AUTOSAR XML (schema 4-1-3)
standard types defined: boolean, uint16, uint32, uint8
package /UAES/ASW/CompuMethods
  compu method CM_boolean: 0=FALSE, 1=TRUE
package /UAES/ASW/DataConstrs
  range DC_boolean: raw 0..1
  range DC_uint16: raw 0..65535
  range DC_uint32: raw 0..4294967295
  range DC_uint8: raw 0..255
package /UAES/ASW/DataTypeMappingSets
  data type mapping set DTMS_ElecDoorHndl_Ctrl
package /UAES/ASW/PortInterfaces
  49 x sender receiver interface:
    gASI_bPowerOnReset: invalidation-policy{data-element=gASI_bPowerOnReset/Val, handle-invalid=DONT-INVALIDATE}
      data Val: sw-calibration-access=READ-ONLY, type=boolean
    gCAN_bLCK_RearLeftDoorHandle: invalidation-policy{data-element=gCAN_bLCK_RearLeftDoorHandle/Val, handle-invalid=DONT-INVALIDATE}
      data Val: sw-calibration-access=READ-ONLY, type=boolean
    gCAN_bLCK_RearRightDoorHandle: invalidation-policy{data-element=gCAN_bLCK_RearRightDoorHandle/Val, handle-invalid=DONT-INVALIDATE}
      data Val: sw-calibration-access=READ-ONLY, type=boolean
    gCAN_u8LCK_DoorHandleCommandActionType: invalidation-policy{data-element=gCAN_u8LCK_DoorHandleCommandActionType/Val, handle-invalid=DONT-INVALIDATE}
      data Val: sw-calibration-access=READ-ONLY, type=uint8
    gEDH_bRLDoorHndlMotorTrigUds: invalidation-policy{data-element=gEDH_bRLDoorHndlMotorTrigUds/Val, handle-invalid=DONT-INVALIDATE}
      data Val: sw-calibration-access=READ-ONLY, type=boolean
    gEDH_bRLHallSupplyOutput: invalidation-policy{data-element=gEDH_bRLHallSupplyOutput/Val, handle-invalid=DONT-INVALIDATE}
      data Val: sw-calibration-access=READ-ONLY, type=boolean
    gEDH_bRRDoorHndlMotorTrigUds: invalidation-policy{data-element=gEDH_bRRDoorHndlMotorTrigUds/Val, handle-invalid=DONT-INVALIDATE}
      data Val: sw-calibration-access=READ-ONLY, type=boolean
    gEDH_bRRHallSupplyOutput: invalidation-policy{data-element=gEDH_bRRHallSupplyOutput/Val, handle-invalid=DONT-INVALIDATE}
      data Val: sw-calibration-access=READ-ONLY, type=boolean
    gEDH_u16RLDoorHandleBigPosition: invalidation-policy{data-element=gEDH_u16RLDoorHandleBigPosition/Val, handle-invalid=DONT-INVALIDATE}
      data Val: sw-calibration-access=READ-ONLY, type=uint16
    gEDH_u16RLDoorHandlePosition: invalidation-policy{data-element=gEDH_u16RLDoorHandlePosition/Val, handle-invalid=DONT-INVALIDATE}
      data Val: sw-calibration-access=READ-ONLY, type=uint16
    gEDH_u16RLDoorHandleSmallPosition: invalidation-policy{data-element=gEDH_u16RLDoorHandleSmallPosition/Val, handle-invalid=DONT-INVALIDATE}
      data Val: sw-calibration-access=READ-ONLY, type=uint16
    gEDH_u16RLHallCnt: invalidation-policy{data-element=gEDH_u16RLHallCnt/Val, handle-invalid=DONT-INVALIDATE}
      data Val: sw-calibration-access=READ-ONLY, type=uint16
    gEDH_u16RLHallWidth: invalidation-policy{data-element=gEDH_u16RLHallWidth/Val, handle-invalid=DONT-INVALIDATE}
      data Val: sw-calibration-access=READ-ONLY, type=uint16
    gEDH_u16RRDoorHandleBigPosition: invalidation-policy{data-element=gEDH_u16RRDoorHandleBigPosition/Val, handle-invalid=DONT-INVALIDATE}
      data Val: sw-calibration-access=READ-ONLY, type=uint16
    gEDH_u16RRDoorHandlePosition: invalidation-policy{data-element=gEDH_u16RRDoorHandlePosition/Val, handle-invalid=DONT-INVALIDATE}
      data Val: sw-calibration-access=READ-ONLY, type=uint16
    gEDH_u16RRDoorHandleSmallPosition: invalidation-policy{data-element=gEDH_u16RRDoorHandleSmallPosition/Val, handle-invalid=DONT-INVALIDATE}
      data Val: sw-calibration-access=READ-ONLY, type=uint16
    gEDH_u16RRHallCnt: invalidation-policy{data-element=gEDH_u16RRHallCnt/Val, handle-invalid=DONT-INVALIDATE}
      data Val: sw-calibration-access=READ-ONLY, type=uint16
    gEDH_u16RRHallWidth: invalidation-policy{data-element=gEDH_u16RRHallWidth/Val, handle-invalid=DONT-INVALIDATE}
      data Val: sw-calibration-access=READ-ONLY, type=uint16
    gEDH_u32AllowSleep_Local: invalidation-policy{data-element=gEDH_u32AllowSleep_Local/Val, handle-invalid=DONT-INVALIDATE}
      data Val: sw-calibration-access=READ-ONLY, type=uint32
    gEDH_u32AllowSleep_NW: invalidation-policy{data-element=gEDH_u32AllowSleep_NW/Val, handle-invalid=DONT-INVALIDATE}
      data Val: sw-calibration-access=READ-ONLY, type=uint32
    gEDH_u8LCK_RearLeftDoorHandleAction: invalidation-policy{data-element=gEDH_u8LCK_RearLeftDoorHandleAction/Val, handle-invalid=DONT-INVALIDATE}
      data Val: sw-calibration-access=READ-ONLY, type=uint8
    gEDH_u8LCK_RearLeftDoorHandlePosition: invalidation-policy{data-element=gEDH_u8LCK_RearLeftDoorHandlePosition/Val, handle-invalid=DONT-INVALIDATE}
      data Val: sw-calibration-access=READ-ONLY, type=uint8
    gEDH_u8LCK_RearRightDoorHandleAction: invalidation-policy{data-element=gEDH_u8LCK_RearRightDoorHandleAction/Val, handle-invalid=DONT-INVALIDATE}
      data Val: sw-calibration-access=READ-ONLY, type=uint8
    gEDH_u8LCK_RearRightDoorHandlePosition: invalidation-policy{data-element=gEDH_u8LCK_RearRightDoorHandlePosition/Val, handle-invalid=DONT-INVALIDATE}
      data Val: sw-calibration-access=READ-ONLY, type=uint8
    gEDH_u8RLDoorHandleBigPositionWrtCnt: invalidation-policy{data-element=gEDH_u8RLDoorHandleBigPositionWrtCnt/Val, handle-invalid=DONT-INVALIDATE}
      data Val: sw-calibration-access=READ-ONLY, type=uint8
    gEDH_u8RLDoorHandleMotorOutput: invalidation-policy{data-element=gEDH_u8RLDoorHandleMotorOutput/Val, handle-invalid=DONT-INVALIDATE}
      data Val: sw-calibration-access=READ-ONLY, type=uint8
    gEDH_u8RLDoorHandlePositionWrtCnt: invalidation-policy{data-element=gEDH_u8RLDoorHandlePositionWrtCnt/Val, handle-invalid=DONT-INVALIDATE}
      data Val: sw-calibration-access=READ-ONLY, type=uint8
    gEDH_u8RLDoorHandlePWMOutput: invalidation-policy{data-element=gEDH_u8RLDoorHandlePWMOutput/Val, handle-invalid=DONT-INVALIDATE}
      data Val: sw-calibration-access=READ-ONLY, type=uint8
    gEDH_u8RLDoorHandleSmallPositionWrtCnt: invalidation-policy{data-element=gEDH_u8RLDoorHandleSmallPositionWrtCnt/Val, handle-invalid=DONT-INVALIDATE}
      data Val: sw-calibration-access=READ-ONLY, type=uint8
    gEDH_u8RLDoorHndlMotorUds: invalidation-policy{data-element=gEDH_u8RLDoorHndlMotorUds/Val, handle-invalid=DONT-INVALIDATE}
      data Val: sw-calibration-access=READ-ONLY, type=uint8
    gEDH_u8RRDoorHandleBigPositionWrtCnt: invalidation-policy{data-element=gEDH_u8RRDoorHandleBigPositionWrtCnt/Val, handle-invalid=DONT-INVALIDATE}
      data Val: sw-calibration-access=READ-ONLY, type=uint8
    gEDH_u8RRDoorHandleMotorOutput: invalidation-policy{data-element=gEDH_u8RRDoorHandleMotorOutput/Val, handle-invalid=DONT-INVALIDATE}
      data Val: sw-calibration-access=READ-ONLY, type=uint8
    gEDH_u8RRDoorHandlePositionWrtCnt: invalidation-policy{data-element=gEDH_u8RRDoorHandlePositionWrtCnt/Val, handle-invalid=DONT-INVALIDATE}
      data Val: sw-calibration-access=READ-ONLY, type=uint8
    gEDH_u8RRDoorHandlePWMOutput: invalidation-policy{data-element=gEDH_u8RRDoorHandlePWMOutput/Val, handle-invalid=DONT-INVALIDATE}
      data Val: sw-calibration-access=READ-ONLY, type=uint8
    gEDH_u8RRDoorHandleSmallPositionWrtCnt: invalidation-policy{data-element=gEDH_u8RRDoorHandleSmallPositionWrtCnt/Val, handle-invalid=DONT-INVALIDATE}
      data Val: sw-calibration-access=READ-ONLY, type=uint8
    gEDH_u8RRDoorHndlMotorUds: invalidation-policy{data-element=gEDH_u8RRDoorHndlMotorUds/Val, handle-invalid=DONT-INVALIDATE}
      data Val: sw-calibration-access=READ-ONLY, type=uint8
    gElecDoorHndl_u8RLDoorHndlMotorPs: invalidation-policy{data-element=gElecDoorHndl_u8RLDoorHndlMotorPs/Val, handle-invalid=DONT-INVALIDATE}
      data Val: sw-calibration-access=READ-ONLY, type=uint8
    gElecDoorHndl_u8RRDoorHndlMotorPs: invalidation-policy{data-element=gElecDoorHndl_u8RRDoorHndlMotorPs/Val, handle-invalid=DONT-INVALIDATE}
      data Val: sw-calibration-access=READ-ONLY, type=uint8
    gNVM_u16RLDoorHandleBigPosition: invalidation-policy{data-element=gNVM_u16RLDoorHandleBigPosition/Val, handle-invalid=DONT-INVALIDATE}
      data Val: sw-calibration-access=READ-ONLY, type=uint16
    gNVM_u16RLDoorHandlePosition: invalidation-policy{data-element=gNVM_u16RLDoorHandlePosition/Val, handle-invalid=DONT-INVALIDATE}
      data Val: sw-calibration-access=READ-ONLY, type=uint16
    gNVM_u16RLDoorHandleSmallPosition: invalidation-policy{data-element=gNVM_u16RLDoorHandleSmallPosition/Val, handle-invalid=DONT-INVALIDATE}
      data Val: sw-calibration-access=READ-ONLY, type=uint16
    gNVM_u16RRDoorHandleBigPosition: invalidation-policy{data-element=gNVM_u16RRDoorHandleBigPosition/Val, handle-invalid=DONT-INVALIDATE}
      data Val: sw-calibration-access=READ-ONLY, type=uint16
    gNVM_u16RRDoorHandlePosition: invalidation-policy{data-element=gNVM_u16RRDoorHandlePosition/Val, handle-invalid=DONT-INVALIDATE}
      data Val: sw-calibration-access=READ-ONLY, type=uint16
    gNVM_u16RRDoorHandleSmallPosition: invalidation-policy{data-element=gNVM_u16RRDoorHandleSmallPosition/Val, handle-invalid=DONT-INVALIDATE}
      data Val: sw-calibration-access=READ-ONLY, type=uint16
    gPRM_u8tDoorHandleEmergencyCfg: invalidation-policy{data-element=gPRM_u8tDoorHandleEmergencyCfg/Val, handle-invalid=DONT-INVALIDATE}
      data Val: sw-calibration-access=READ-ONLY, type=uint8
    gPRM_u8tDoorHandleForceCfg: invalidation-policy{data-element=gPRM_u8tDoorHandleForceCfg/Val, handle-invalid=DONT-INVALIDATE}
      data Val: sw-calibration-access=READ-ONLY, type=uint8
    gPRM_u8tDoorHandleSoftStopCfg: invalidation-policy{data-element=gPRM_u8tDoorHandleSoftStopCfg/Val, handle-invalid=DONT-INVALIDATE}
      data Val: sw-calibration-access=READ-ONLY, type=uint8
    gPRM_u8tDoorHandleTimeOutCfg: invalidation-policy{data-element=gPRM_u8tDoorHandleTimeOutCfg/Val, handle-invalid=DONT-INVALIDATE}
      data Val: sw-calibration-access=READ-ONLY, type=uint8
    gVRM_u16BatteryVolt_mv: invalidation-policy{data-element=gVRM_u16BatteryVolt_mv/Val, handle-invalid=DONT-INVALIDATE}
      data Val: sw-calibration-access=READ-ONLY, type=uint16
package /UAES/ASW/SwComponentTypes
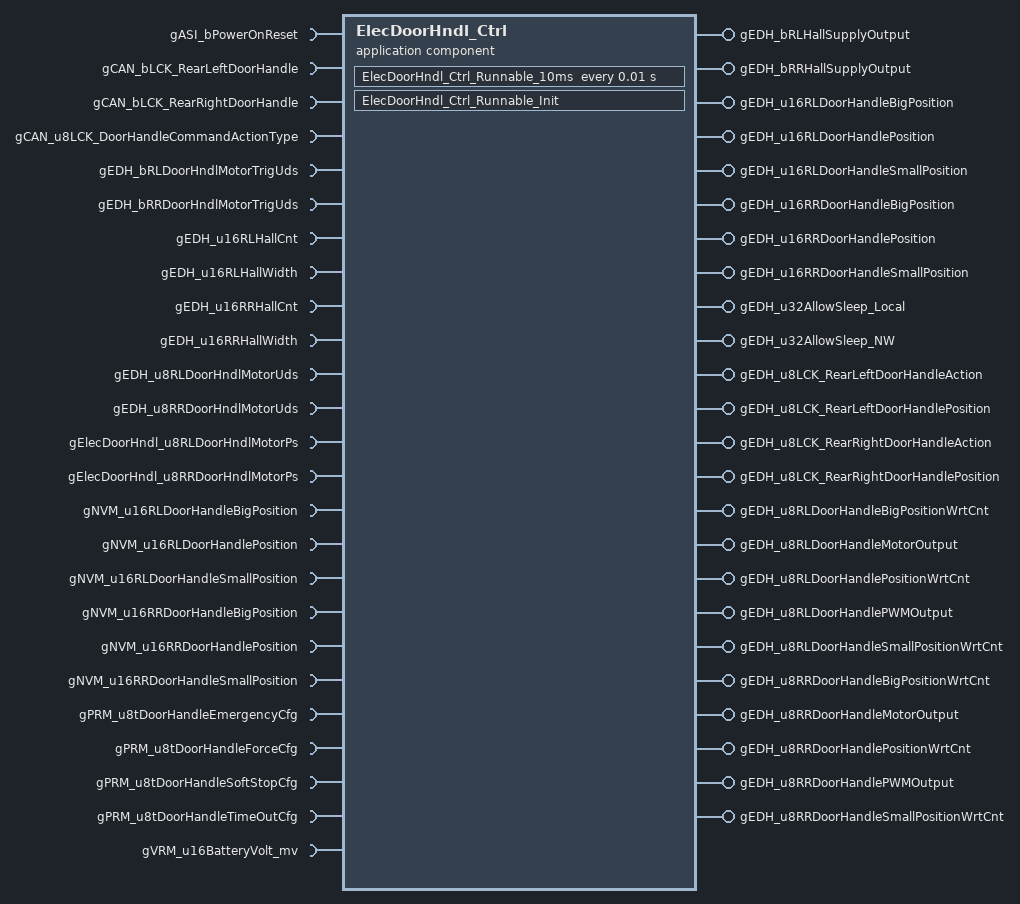
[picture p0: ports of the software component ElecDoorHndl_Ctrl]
  application sw component type ElecDoorHndl_Ctrl
    24 x provide port:
      gEDH_bRLHallSupplyOutput: nonqueued-sender-com-spec{data-element=gEDH_bRLHallSupplyOutput/Val, init-value=0}, provided-interface=gEDH_bRLHallSupplyOutput
      gEDH_bRRHallSupplyOutput: nonqueued-sender-com-spec{data-element=gEDH_bRRHallSupplyOutput/Val, init-value=0}, provided-interface=gEDH_bRRHallSupplyOutput
      gEDH_u16RLDoorHandleBigPosition: nonqueued-sender-com-spec{data-element=gEDH_u16RLDoorHandleBigPosition/Val, init-value=0}, provided-interface=gEDH_u16RLDoorHandleBigPosition
      gEDH_u16RLDoorHandlePosition: nonqueued-sender-com-spec{data-element=gEDH_u16RLDoorHandlePosition/Val, init-value=0}, provided-interface=gEDH_u16RLDoorHandlePosition
      gEDH_u16RLDoorHandleSmallPosition: nonqueued-sender-com-spec{data-element=gEDH_u16RLDoorHandleSmallPosition/Val, init-value=0}, provided-interface=gEDH_u16RLDoorHandleSmallPosition
      gEDH_u16RRDoorHandleBigPosition: nonqueued-sender-com-spec{data-element=gEDH_u16RRDoorHandleBigPosition/Val, init-value=0}, provided-interface=gEDH_u16RRDoorHandleBigPosition
      gEDH_u16RRDoorHandlePosition: nonqueued-sender-com-spec{data-element=gEDH_u16RRDoorHandlePosition/Val, init-value=0}, provided-interface=gEDH_u16RRDoorHandlePosition
      gEDH_u16RRDoorHandleSmallPosition: nonqueued-sender-com-spec{data-element=gEDH_u16RRDoorHandleSmallPosition/Val, init-value=0}, provided-interface=gEDH_u16RRDoorHandleSmallPosition
      gEDH_u32AllowSleep_Local: nonqueued-sender-com-spec{data-element=gEDH_u32AllowSleep_Local/Val, init-value=0}, provided-interface=gEDH_u32AllowSleep_Local
      gEDH_u32AllowSleep_NW: nonqueued-sender-com-spec{data-element=gEDH_u32AllowSleep_NW/Val, init-value=0}, provided-interface=gEDH_u32AllowSleep_NW
      gEDH_u8LCK_RearLeftDoorHandleAction: nonqueued-sender-com-spec{data-element=gEDH_u8LCK_RearLeftDoorHandleAction/Val, init-value=0}, provided-interface=gEDH_u8LCK_RearLeftDoorHandleAction
      gEDH_u8LCK_RearLeftDoorHandlePosition: nonqueued-sender-com-spec{data-element=gEDH_u8LCK_RearLeftDoorHandlePosition/Val, init-value=0}, provided-interface=gEDH_u8LCK_RearLeftDoorHandlePosition
      gEDH_u8LCK_RearRightDoorHandleAction: nonqueued-sender-com-spec{data-element=gEDH_u8LCK_RearRightDoorHandleAction/Val, init-value=0}, provided-interface=gEDH_u8LCK_RearRightDoorHandleAction
      gEDH_u8LCK_RearRightDoorHandlePosition: nonqueued-sender-com-spec{data-element=gEDH_u8LCK_RearRightDoorHandlePosition/Val, init-value=0}, provided-interface=gEDH_u8LCK_RearRightDoorHandlePosition
      gEDH_u8RLDoorHandleBigPositionWrtCnt: nonqueued-sender-com-spec{data-element=gEDH_u8RLDoorHandleBigPositionWrtCnt/Val, init-value=0}, provided-interface=gEDH_u8RLDoorHandleBigPositionWrtCnt
      gEDH_u8RLDoorHandleMotorOutput: nonqueued-sender-com-spec{data-element=gEDH_u8RLDoorHandleMotorOutput/Val, init-value=0}, provided-interface=gEDH_u8RLDoorHandleMotorOutput
      gEDH_u8RLDoorHandlePositionWrtCnt: nonqueued-sender-com-spec{data-element=gEDH_u8RLDoorHandlePositionWrtCnt/Val, init-value=0}, provided-interface=gEDH_u8RLDoorHandlePositionWrtCnt
      gEDH_u8RLDoorHandlePWMOutput: nonqueued-sender-com-spec{data-element=gEDH_u8RLDoorHandlePWMOutput/Val, init-value=0}, provided-interface=gEDH_u8RLDoorHandlePWMOutput
      gEDH_u8RLDoorHandleSmallPositionWrtCnt: nonqueued-sender-com-spec{data-element=gEDH_u8RLDoorHandleSmallPositionWrtCnt/Val, init-value=0}, provided-interface=gEDH_u8RLDoorHandleSmallPositionWrtCnt
      gEDH_u8RRDoorHandleBigPositionWrtCnt: nonqueued-sender-com-spec{data-element=gEDH_u8RRDoorHandleBigPositionWrtCnt/Val, init-value=0}, provided-interface=gEDH_u8RRDoorHandleBigPositionWrtCnt
      gEDH_u8RRDoorHandleMotorOutput: nonqueued-sender-com-spec{data-element=gEDH_u8RRDoorHandleMotorOutput/Val, init-value=0}, provided-interface=gEDH_u8RRDoorHandleMotorOutput
      gEDH_u8RRDoorHandlePositionWrtCnt: nonqueued-sender-com-spec{data-element=gEDH_u8RRDoorHandlePositionWrtCnt/Val, init-value=0}, provided-interface=gEDH_u8RRDoorHandlePositionWrtCnt
      gEDH_u8RRDoorHandlePWMOutput: nonqueued-sender-com-spec{data-element=gEDH_u8RRDoorHandlePWMOutput/Val, init-value=0}, provided-interface=gEDH_u8RRDoorHandlePWMOutput
      gEDH_u8RRDoorHandleSmallPositionWrtCnt: nonqueued-sender-com-spec{data-element=gEDH_u8RRDoorHandleSmallPositionWrtCnt/Val, init-value=0}, provided-interface=gEDH_u8RRDoorHandleSmallPositionWrtCnt
    25 x require port:
      gASI_bPowerOnReset: nonqueued-receiver-com-spec{data-element=gASI_bPowerOnReset/Val, filter=data-filter-type=ALWAYS, init-value=0}, required-interface=gASI_bPowerOnReset
      gCAN_bLCK_RearLeftDoorHandle: nonqueued-receiver-com-spec{data-element=gCAN_bLCK_RearLeftDoorHandle/Val, filter=data-filter-type=ALWAYS, init-value=0}, required-interface=gCAN_bLCK_RearLeftDoorHandle
      gCAN_bLCK_RearRightDoorHandle: nonqueued-receiver-com-spec{data-element=gCAN_bLCK_RearRightDoorHandle/Val, filter=data-filter-type=ALWAYS, init-value=0}, required-interface=gCAN_bLCK_RearRightDoorHandle
      gCAN_u8LCK_DoorHandleCommandActionType: nonqueued-receiver-com-spec{data-element=gCAN_u8LCK_DoorHandleCommandActionType/Val, filter=data-filter-type=ALWAYS, init-value=0}, required-interface=gCAN_u8LCK_DoorHandleCommandActionType
      gEDH_bRLDoorHndlMotorTrigUds: nonqueued-receiver-com-spec{data-element=gEDH_bRLDoorHndlMotorTrigUds/Val, filter=data-filter-type=ALWAYS, init-value=0}, required-interface=gEDH_bRLDoorHndlMotorTrigUds
      gEDH_bRRDoorHndlMotorTrigUds: nonqueued-receiver-com-spec{data-element=gEDH_bRRDoorHndlMotorTrigUds/Val, filter=data-filter-type=ALWAYS, init-value=0}, required-interface=gEDH_bRRDoorHndlMotorTrigUds
      gEDH_u16RLHallCnt: nonqueued-receiver-com-spec{data-element=gEDH_u16RLHallCnt/Val, filter=data-filter-type=ALWAYS, init-value=0}, required-interface=gEDH_u16RLHallCnt
      gEDH_u16RLHallWidth: nonqueued-receiver-com-spec{data-element=gEDH_u16RLHallWidth/Val, filter=data-filter-type=ALWAYS, init-value=0}, required-interface=gEDH_u16RLHallWidth
      gEDH_u16RRHallCnt: nonqueued-receiver-com-spec{data-element=gEDH_u16RRHallCnt/Val, filter=data-filter-type=ALWAYS, init-value=0}, required-interface=gEDH_u16RRHallCnt
      gEDH_u16RRHallWidth: nonqueued-receiver-com-spec{data-element=gEDH_u16RRHallWidth/Val, filter=data-filter-type=ALWAYS, init-value=0}, required-interface=gEDH_u16RRHallWidth
      gEDH_u8RLDoorHndlMotorUds: nonqueued-receiver-com-spec{data-element=gEDH_u8RLDoorHndlMotorUds/Val, filter=data-filter-type=ALWAYS, init-value=0}, required-interface=gEDH_u8RLDoorHndlMotorUds
      gEDH_u8RRDoorHndlMotorUds: nonqueued-receiver-com-spec{data-element=gEDH_u8RRDoorHndlMotorUds/Val, filter=data-filter-type=ALWAYS, init-value=0}, required-interface=gEDH_u8RRDoorHndlMotorUds
      gElecDoorHndl_u8RLDoorHndlMotorPs: nonqueued-receiver-com-spec{data-element=gElecDoorHndl_u8RLDoorHndlMotorPs/Val, filter=data-filter-type=ALWAYS, init-value=0}, required-interface=gElecDoorHndl_u8RLDoorHndlMotorPs
      gElecDoorHndl_u8RRDoorHndlMotorPs: nonqueued-receiver-com-spec{data-element=gElecDoorHndl_u8RRDoorHndlMotorPs/Val, filter=data-filter-type=ALWAYS, init-value=0}, required-interface=gElecDoorHndl_u8RRDoorHndlMotorPs
      gNVM_u16RLDoorHandleBigPosition: nonqueued-receiver-com-spec{data-element=gNVM_u16RLDoorHandleBigPosition/Val, filter=data-filter-type=ALWAYS, init-value=0}, required-interface=gNVM_u16RLDoorHandleBigPosition
      gNVM_u16RLDoorHandlePosition: nonqueued-receiver-com-spec{data-element=gNVM_u16RLDoorHandlePosition/Val, filter=data-filter-type=ALWAYS, init-value=0}, required-interface=gNVM_u16RLDoorHandlePosition
      gNVM_u16RLDoorHandleSmallPosition: nonqueued-receiver-com-spec{data-element=gNVM_u16RLDoorHandleSmallPosition/Val, filter=data-filter-type=ALWAYS, init-value=0}, required-interface=gNVM_u16RLDoorHandleSmallPosition
      gNVM_u16RRDoorHandleBigPosition: nonqueued-receiver-com-spec{data-element=gNVM_u16RRDoorHandleBigPosition/Val, filter=data-filter-type=ALWAYS, init-value=0}, required-interface=gNVM_u16RRDoorHandleBigPosition
      gNVM_u16RRDoorHandlePosition: nonqueued-receiver-com-spec{data-element=gNVM_u16RRDoorHandlePosition/Val, filter=data-filter-type=ALWAYS, init-value=0}, required-interface=gNVM_u16RRDoorHandlePosition
      gNVM_u16RRDoorHandleSmallPosition: nonqueued-receiver-com-spec{data-element=gNVM_u16RRDoorHandleSmallPosition/Val, filter=data-filter-type=ALWAYS, init-value=0}, required-interface=gNVM_u16RRDoorHandleSmallPosition
      gPRM_u8tDoorHandleEmergencyCfg: nonqueued-receiver-com-spec{data-element=gPRM_u8tDoorHandleEmergencyCfg/Val, filter=data-filter-type=ALWAYS, init-value=0}, required-interface=gPRM_u8tDoorHandleEmergencyCfg
      gPRM_u8tDoorHandleForceCfg: nonqueued-receiver-com-spec{data-element=gPRM_u8tDoorHandleForceCfg/Val, filter=data-filter-type=ALWAYS, init-value=0}, required-interface=gPRM_u8tDoorHandleForceCfg
      gPRM_u8tDoorHandleSoftStopCfg: nonqueued-receiver-com-spec{data-element=gPRM_u8tDoorHandleSoftStopCfg/Val, filter=data-filter-type=ALWAYS, init-value=0}, required-interface=gPRM_u8tDoorHandleSoftStopCfg
      gPRM_u8tDoorHandleTimeOutCfg: nonqueued-receiver-com-spec{data-element=gPRM_u8tDoorHandleTimeOutCfg/Val, filter=data-filter-type=ALWAYS, init-value=0}, required-interface=gPRM_u8tDoorHandleTimeOutCfg
      gVRM_u16BatteryVolt_mv: nonqueued-receiver-com-spec{data-element=gVRM_u16BatteryVolt_mv/Val, filter=data-filter-type=ALWAYS, init-value=0}, required-interface=gVRM_u16BatteryVolt_mv
    behavior ElecDoorHndl_Ctrl_InternalBehavior: data-type-mapping=DTMS_ElecDoorHndl_Ctrl
      timing event TMT_ElecDoorHndl_Ctrl_Runnable_10ms: start-on-event=ElecDoorHndl_Ctrl_Runnable_10ms, period=0.01
      init event ElecDoorHndl_Ctrl_InitEvent: start-on-event=ElecDoorHndl_Ctrl_Runnable_Init
      runnable ElecDoorHndl_Ctrl_Runnable_10ms
        data-receive-point-by-arguments:
          25 x access:
            IN_gASI_bPowerOnReset_Val: accessed-variable=gASI_bPowerOnReset.Val
            IN_gCAN_u8LCK_DoorHandleCommandActionType_Val: accessed-variable=gCAN_u8LCK_DoorHandleCommandActionType.Val
            IN_gEDH_u16RLHallCnt_Val: accessed-variable=gEDH_u16RLHallCnt.Val
            IN_gEDH_u16RLHallWidth_Val: accessed-variable=gEDH_u16RLHallWidth.Val
            IN_gEDH_u16RRHallCnt_Val: accessed-variable=gEDH_u16RRHallCnt.Val
            IN_gEDH_u16RRHallWidth_Val: accessed-variable=gEDH_u16RRHallWidth.Val
            IN_gNVM_u16RLDoorHandleBigPosition_Val: accessed-variable=gNVM_u16RLDoorHandleBigPosition.Val
            IN_gNVM_u16RLDoorHandlePosition_Val: accessed-variable=gNVM_u16RLDoorHandlePosition.Val
            IN_gNVM_u16RLDoorHandleSmallPosition_Val: accessed-variable=gNVM_u16RLDoorHandleSmallPosition.Val
            IN_gNVM_u16RRDoorHandleBigPosition_Val: accessed-variable=gNVM_u16RRDoorHandleBigPosition.Val
            IN_gNVM_u16RRDoorHandlePosition_Val: accessed-variable=gNVM_u16RRDoorHandlePosition.Val
            IN_gNVM_u16RRDoorHandleSmallPosition_Val: accessed-variable=gNVM_u16RRDoorHandleSmallPosition.Val
            IN_gPRM_u8tDoorHandleEmergencyCfg_Val: accessed-variable=gPRM_u8tDoorHandleEmergencyCfg.Val
            IN_gPRM_u8tDoorHandleForceCfg_Val: accessed-variable=gPRM_u8tDoorHandleForceCfg.Val
            IN_gPRM_u8tDoorHandleSoftStopCfg_Val: accessed-variable=gPRM_u8tDoorHandleSoftStopCfg.Val
            IN_gPRM_u8tDoorHandleTimeOutCfg_Val: accessed-variable=gPRM_u8tDoorHandleTimeOutCfg.Val
            IN_gVRM_u16BatteryVolt_mv_Val: accessed-variable=gVRM_u16BatteryVolt_mv.Val
            REC_gCAN_bLCK_RearLeftDoorHandle_Val: accessed-variable=gCAN_bLCK_RearLeftDoorHandle.Val
            REC_gCAN_bLCK_RearRightDoorHandle_Val: accessed-variable=gCAN_bLCK_RearRightDoorHandle.Val
            REC_gEDH_bRLDoorHndlMotorTrigUds_Val: accessed-variable=gEDH_bRLDoorHndlMotorTrigUds.Val
            REC_gEDH_bRRDoorHndlMotorTrigUds_Val: accessed-variable=gEDH_bRRDoorHndlMotorTrigUds.Val
            REC_gEDH_u8RLDoorHndlMotorUds_Val: accessed-variable=gEDH_u8RLDoorHndlMotorUds.Val
            REC_gEDH_u8RRDoorHndlMotorUds_Val: accessed-variable=gEDH_u8RRDoorHndlMotorUds.Val
            REC_gElecDoorHndl_u8RLDoorHndlMotorPs_Val: accessed-variable=gElecDoorHndl_u8RLDoorHndlMotorPs.Val
            REC_gElecDoorHndl_u8RRDoorHndlMotorPs_Val: accessed-variable=gElecDoorHndl_u8RRDoorHndlMotorPs.Val
        data-send-points:
          24 x access:
            OUT_gEDH_bRLHallSupplyOutput_Val: accessed-variable=gEDH_bRLHallSupplyOutput.Val
            OUT_gEDH_bRRHallSupplyOutput_Val: accessed-variable=gEDH_bRRHallSupplyOutput.Val
            OUT_gEDH_u16RLDoorHandleBigPosition_Val: accessed-variable=gEDH_u16RLDoorHandleBigPosition.Val
            OUT_gEDH_u16RLDoorHandlePosition_Val: accessed-variable=gEDH_u16RLDoorHandlePosition.Val
            OUT_gEDH_u16RLDoorHandleSmallPosition_Val: accessed-variable=gEDH_u16RLDoorHandleSmallPosition.Val
            OUT_gEDH_u16RRDoorHandleBigPosition_Val: accessed-variable=gEDH_u16RRDoorHandleBigPosition.Val
            OUT_gEDH_u16RRDoorHandlePosition_Val: accessed-variable=gEDH_u16RRDoorHandlePosition.Val
            OUT_gEDH_u16RRDoorHandleSmallPosition_Val: accessed-variable=gEDH_u16RRDoorHandleSmallPosition.Val
            OUT_gEDH_u32AllowSleep_Local_Val: accessed-variable=gEDH_u32AllowSleep_Local.Val
            OUT_gEDH_u32AllowSleep_NW_Val: accessed-variable=gEDH_u32AllowSleep_NW.Val
            OUT_gEDH_u8LCK_RearLeftDoorHandleAction_Val: accessed-variable=gEDH_u8LCK_RearLeftDoorHandleAction.Val
            OUT_gEDH_u8LCK_RearLeftDoorHandlePosition_Val: accessed-variable=gEDH_u8LCK_RearLeftDoorHandlePosition.Val
            OUT_gEDH_u8LCK_RearRightDoorHandleAction_Val: accessed-variable=gEDH_u8LCK_RearRightDoorHandleAction.Val
            OUT_gEDH_u8LCK_RearRightDoorHandlePosition_Val: accessed-variable=gEDH_u8LCK_RearRightDoorHandlePosition.Val
            OUT_gEDH_u8RLDoorHandleBigPositionWrtCnt_Val: accessed-variable=gEDH_u8RLDoorHandleBigPositionWrtCnt.Val
            OUT_gEDH_u8RLDoorHandleMotorOutput_Val: accessed-variable=gEDH_u8RLDoorHandleMotorOutput.Val
            OUT_gEDH_u8RLDoorHandlePositionWrtCnt_Val: accessed-variable=gEDH_u8RLDoorHandlePositionWrtCnt.Val
            OUT_gEDH_u8RLDoorHandlePWMOutput_Val: accessed-variable=gEDH_u8RLDoorHandlePWMOutput.Val
            OUT_gEDH_u8RLDoorHandleSmallPositionWrtCnt_Val: accessed-variable=gEDH_u8RLDoorHandleSmallPositionWrtCnt.Val
            OUT_gEDH_u8RRDoorHandleBigPositionWrtCnt_Val: accessed-variable=gEDH_u8RRDoorHandleBigPositionWrtCnt.Val
            OUT_gEDH_u8RRDoorHandleMotorOutput_Val: accessed-variable=gEDH_u8RRDoorHandleMotorOutput.Val
            OUT_gEDH_u8RRDoorHandlePositionWrtCnt_Val: accessed-variable=gEDH_u8RRDoorHandlePositionWrtCnt.Val
            OUT_gEDH_u8RRDoorHandlePWMOutput_Val: accessed-variable=gEDH_u8RRDoorHandlePWMOutput.Val
            OUT_gEDH_u8RRDoorHandleSmallPositionWrtCnt_Val: accessed-variable=gEDH_u8RRDoorHandleSmallPositionWrtCnt.Val
      runnable ElecDoorHndl_Ctrl_Runnable_Init
  swc implementation Implementation_ElecDoorHndl_Ctrl: behavior=ElecDoorHndl_Ctrl_InternalBehavior
    code-descriptors:
      code Default: artifact-descriptors=autosar-engineering-object={short-label=Default, category=SWSRC}
package /UAES/ASW/Units
  unit NoUnit: factor-si-to-unit=1, offset-si-to-unit=0
